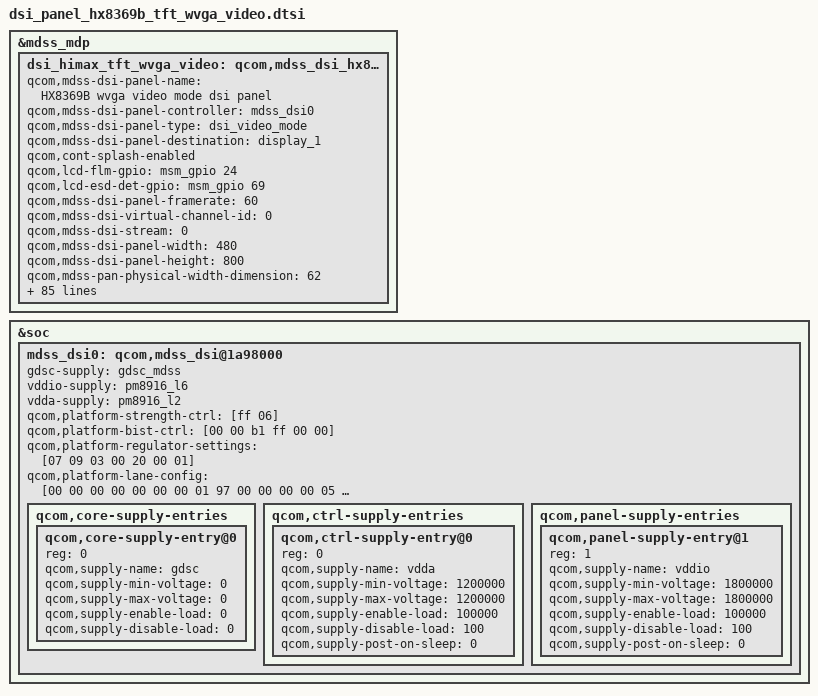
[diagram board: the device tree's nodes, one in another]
/* Copyright (c) 2013-14, Samsung Electronics Corporation. All rights reserved.
 *
 * This program is free software; you can redistribute it and/or modify
 * it under the terms of the GNU General Public License version 2 and
 * only version 2 as published by the Free Software Foundation.
 *
 * This program is distributed in the hope that it will be useful,
 * but WITHOUT ANY WARRANTY; without even the implied warranty of
 * MERCHANTABILITY or FITNESS FOR A PARTICULAR PURPOSE.  See the
 * GNU General Public License for more details.
 */

/*---------------------------------------------------------------------------
 * This file is autogenerated file using gcdb parser. Please do not edit it.
 * Update input XML file to add a new entry or update variable in this file
 * VERSION = "1.0"
 *---------------------------------------------------------------------------

 */
&mdss_mdp {
	dsi_himax_tft_wvga_video: qcom,mdss_dsi_hx8369b_wvga_video {
		qcom,mdss-dsi-panel-name = "HX8369B wvga video mode dsi panel";
		qcom,mdss-dsi-panel-controller = <&mdss_dsi0>;
		qcom,mdss-dsi-panel-type = "dsi_video_mode";
		qcom,mdss-dsi-panel-destination = "display_1";
		qcom,cont-splash-enabled;
		qcom,lcd-flm-gpio = <&msm_gpio 24 0>;
		qcom,lcd-esd-det-gpio = <&msm_gpio 69 0>;
		qcom,mdss-dsi-panel-framerate = <60>;
		qcom,mdss-dsi-virtual-channel-id = <0>;
		qcom,mdss-dsi-stream = <0>;
		qcom,mdss-dsi-panel-width = <480>;
		qcom,mdss-dsi-panel-height = <800>;
		qcom,mdss-pan-physical-width-dimension = <62>; /* <Width> real size of panel in mm */
		qcom,mdss-pan-physical-height-dimension = <106>; /*<Height> real size of panel in mm */
		qcom,mdss-dsi-lp11-init;
		qcom,mdss-dsi-init-delay-us = <100>;
		qcom,mdss-dsi-h-front-porch = <110>;
		qcom,mdss-dsi-h-back-porch = <246>;
		qcom,mdss-dsi-h-pulse-width = <4>;
		qcom,mdss-dsi-h-sync-skew = <0>;
		qcom,mdss-dsi-v-back-porch = <12>;
		qcom,mdss-dsi-v-front-porch = <10>;
		qcom,mdss-dsi-v-pulse-width = <4>;
		qcom,mdss-dsi-h-front-porch-dtc = <110>;
		qcom,mdss-dsi-h-back-porch-dtc = <110>;
		qcom,mdss-dsi-h-pulse-width-dtc = <4>;
		qcom,mdss-dsi-v-back-porch-dtc = <12>;
		qcom,mdss-dsi-v-front-porch-dtc= <10>;
		qcom,mdss-dsi-v-pulse-width-dtc = <4>;
		qcom,mdss-dsi-h-front-porch-sc7798a-boe = <140>;/*<SC7798A porch&timing>*/
		qcom,mdss-dsi-h-back-porch-sc7798a-boe = <132>;
		qcom,mdss-dsi-h-pulse-width-sc7798a-boe = <4>;
		qcom,mdss-dsi-v-front-porch-sc7798a-boe= <10>;
		qcom,mdss-dsi-v-back-porch-sc7798a-boe = <12>;
		qcom,mdss-dsi-v-pulse-width-sc7798a-boe = <4>;
		qcom,mdss-dsi-panel-timings-sc7798a-boe = [33 1A 10 00 3E 40 16 1E 15 03 04 00];
		qcom,mdss-dsi-t-clk-pre-sc7798a-boe = <0x18>;
		qcom,mdss-dsi-t-clk-post-sc7798a-boe = <0x04>;/*<END SC7798A porch&timing>*/
		qcom,mdss-dsi-h-front-porch-boe = <110>;
		qcom,mdss-dsi-h-back-porch-boe = <110>;
		qcom,mdss-dsi-h-back-porch-boe-ctc = <110>;/*MIPI 408Mhz porch for Rossa CTC*/
		qcom,mdss-dsi-h-pulse-width-boe = <4>;
		qcom,mdss-dsi-v-back-porch-boe = <12>;
		qcom,mdss-dsi-v-front-porch-boe= <10>;
		qcom,mdss-dsi-v-pulse-width-boe = <4>;
		qcom,mdss-dsi-h-left-border = <0>;
		qcom,mdss-dsi-h-right-border = <0>;
		qcom,mdss-dsi-v-top-border = <0>;
		qcom,mdss-dsi-v-bottom-border = <0>;
		qcom,mdss-dsi-bpp = <24>;
		qcom,mdss-dsi-color-order = <0>;
		qcom,mdss-dsi-underflow-color = <0xff>;
		qcom,mdss-dsi-border-color = <0>;
		qcom,mdss-dsi-dma-trigger = "trigger_sw";
		qcom,mdss-dsi-mdp-trigger = "none";
		qcom,mdss-dsi-bl-min-level = <1>;
		qcom,mdss-dsi-bl-max-level = <255>;
		qcom,mdss-dsi-bl-pmic-control-type = "bl_ctrl_dcs";
		qcom,mdss-dsi-lane-0-state;
		qcom,mdss-dsi-lane-1-state;
		qcom,mdss-dsi-bllp-eof-power-mode;
		qcom,mdss-dsi-bllp-power-mode;
		qcom,mdss-dsi-traffic-mode = "burst_mode";
		qcom,mdss-force-clk-lane-hs = <0>;
		qcom,mdss-dsi-reset-sequence = <1 20>, <0 1>, <1 20>;
		qcom,mdss-dsi-h-sync-pulse = <0>;
		qcom,mdss-dsi-panel-timings = [88 33 14 00 45 4A 19 37 23 03 04 00];
		qcom,mdss-dsi-t-clk-pre = <0x1D>;
		qcom,mdss-dsi-t-clk-post = <0x04>;
		qcom,mdss-dsi-panel-timings-dtc = [51 14 0C 00 36 38 12 18 1B 03 04 00];
		qcom,mdss-dsi-t-clk-pre-dtc = <0x15>;
		qcom,mdss-dsi-t-clk-post-dtc = <0x04>;
		qcom,mdss-dsi-panel-timings-boe = [E3 1A 10 00 3E 40 16 1E 15 03 04 00];
		qcom,mdss-dsi-panel-timings-boe-ctc = [88 33 14 00 45 4A 19 37 23 03 04 00];/*MIPI 408Mhz timing for Rossa CTC*/
		qcom,mdss-dsi-t-clk-pre-boe = <0x25>;
		qcom,mdss-dsi-t-clk-post-boe = <0x04>;
		qcom,mdss-dsi-on-command = [
					/* < Power Setting Sequence(1) > */
					39 01 00 00 00 00 06 F0 55 AA 52 08 01
					39 01 00 00 00 00 02 B0 08
					39 01 00 00 00 00 02 B2 40
					39 01 00 00 00 00 02 B3 28
					39 01 00 00 00 00 02 B4 19
					39 01 00 00 00 00 02 B5 54
					39 01 00 00 00 00 02 B9 36
					39 01 00 00 00 00 02 BA 26
					39 01 00 00 00 00 03 BC A0 00
					39 01 00 00 00 00 03 BD A0 00
					/* < Gamma Setting Sequence(3) > */
					39 01 00 00 00 00 11 D1 65 00 00 88 00 C9 00 D7 00 EB 01 12 01 33 01 65
					39 01 00 00 00 00 11 D2 01 8B 01 C2 01 EA 02 21 02 4C 02 4D 02 72 02 96
					39 01 00 00 00 00 11 D3 02 AA 02 C1 02 CF 02 E3 02 EF 02 FF 03 0B 03 1B
					39 01 00 00 00 00 05 D4 03 3A 03 9A
					39 01 00 00 00 00 11 D5 65 00 00 88 00 C9 00 D7 00 EB 01 12 01 33 01 65
					39 01 00 00 00 00 11 D6 01 8B 01 C2 01 EA 02 21 02 4C 02 4D 02 72 02 96
					39 01 00 00 00 00 11 D7 02 AA 02 C1 02 CF 02 E3 02 EF 02 FF 03 0B 03 1B
					39 01 00 00 00 00 05 D8 03 3A 03 9A
					39 01 00 00 00 00 11 D9 65 00 00 88 00 C9 00 D7 00 EB 01 12 01 33 01 65
					39 01 00 00 00 00 11 DD 01 8B 01 C2 01 EA 02 21 02 4C 02 4D 02 72 02 96
					39 01 00 00 00 00 11 DE 02 AA 02 C1 02 CF 02 E3 02 EF 02 FF 03 0B 03 1B
					39 01 00 00 00 00 05 DF 03 3A 03 9A
					39 01 00 00 00 00 11 E0 00 3B 00 5E 00 C9 00 D7 00 EB 01 12 01 33 01 65
					39 01 00 00 00 00 11 E1 01 8B 01 C2 01 EA 02 21 02 4C 02 4D 02 72 02 96
					39 01 00 00 00 00 11 E2 02 AA 02 C1 02 CF 02 E3 02 EF 02 FF 03 0B 03 1B
					39 01 00 00 00 00 05 E3 03 3A 03 9A
					39 01 00 00 00 00 11 E4 00 3B 00 5E 00 C9 00 D7 00 EB 01 12 01 33 01 65
					39 01 00 00 00 00 11 E5 01 8B 01 C2 01 EA 02 21 02 4C 02 4D 02 72 02 96
					39 01 00 00 00 00 11 E6 02 AA 02 C1 02 CF 02 E3 02 EF 02 FF 03 0B 03 1B
					39 01 00 00 00 00 05 E7 03 3A 03 9A
					39 01 00 00 00 00 11 E8 00 3B 00 5E 00 C9 00 D7 00 EB 01 12 01 33 01 65
					39 01 00 00 00 00 11 E9 01 8B 01 C2 01 EA 02 21 02 4C 02 4D 02 72 02 96
					39 01 00 00 00 00 11 EA 02 AA 02 C1 02 CF 02 E3 02 EF 02 FF 03 0B 03 1B
					39 01 00 00 00 00 05 EB 03 3A 03 9A
					/* < Initializing Sequence(2) > */
					39 01 00 00 00 00 06 F0 55 AA 52 08 00
					39 01 00 00 00 00 03 B1 16 00
					39 01 00 00 00 00 03 B3 61 02
					39 01 00 00 00 00 03 B4 08 50
					39 01 00 00 00 00 02 B6 03
					39 01 00 00 00 00 03 B7 F0 F0
					39 01 00 00 00 00 03 B8 01 07
					39 01 00 00 00 00 02 BC 02
					39 01 00 00 00 00 04 BB FF F5 00
					39 01 00 00 00 00 13 C8 80 00 46 64 46 64 46 64 46 64 64 FF FF 64 64 64 64 64
					39 01 00 00 00 00 02 B3 20
					39 01 00 00 00 00 06 F0 55 AA 52 00 00
					39 01 00 00 00 00 05 FF AA 55 25 01
					39 01 00 00 00 00 02 6F 02
					39 01 00 00 00 00 02 F4 57
					39 01 00 00 00 00 02 6F 13
					39 01 00 00 00 00 02 F2 16
					39 01 00 00 00 00 05 FF AA 55 25 00
					39 01 00 00 00 00 02 B3 20
					39 01 00 00 00 00 02 36 00
					39 01 00 00 00 00 02 35 00
					/* < Display on Sequence> */
					05 01 00 00 78 00 02 11 00
					05 01 00 00 0A 00 02 29 00
					/* Test Screen Mode */
					/*
					39 01 00 00 00 00 06 F0 55 AA 52 08 00
					39 01 00 00 00 00 05 EE 87 78 02 40
					*/
					39 01 00 00 00 00 02 55 00
					39 01 00 00 00 00 02 53 2C
					];
		qcom,mdss-dsi-on-command-dtc = [
					/* < Power Setting Sequence(1) > */
					39 01 00 00 00 00 06 F0 55 AA 52 08 01
					39 01 00 00 00 00 02 B0 0C
					39 01 00 00 00 00 02 B2 41
					39 01 00 00 00 00 02 B3 1E
					39 01 00 00 00 00 02 B4 19
					39 01 00 00 00 00 02 B5 64
					39 01 00 00 00 00 02 B9 36
					39 01 00 00 00 00 02 BA 26
					39 01 00 00 00 00 03 BC 66 00
					39 01 00 00 00 00 03 BD 66 00
					39 01 00 00 00 00 02 6F 02
					39 01 00 00 0A 00 02 C8 C0
					/* < Gamma Setting Sequence(3) > */
					39 01 00 00 00 00 11 D1 00 00 00 01 00 07 00 1D 00 3A 00 7A 00 AE 00 FC
					39 01 00 00 00 00 11 D2 01 33 01 7A 01 AB 01 EC 02 1D 02 1E 02 48 02 6F
					39 01 00 00 00 00 11 D3 02 82 02 99 02 A5 02 B4 02 BB 02 C4 02 C9 02 CF
					39 01 00 00 00 00 05 D4 02 D5 02 F0
					39 01 00 00 00 00 11 E0 00 00 00 01 00 07 00 1D 00 3A 00 7A 00 AE 00 FC
					39 01 00 00 00 00 11 E1 01 33 01 7A 01 AB 01 EC 02 1D 02 1E 02 48 02 6F
					39 01 00 00 00 00 11 E2 02 82 02 99 02 A5 02 B4 02 BB 02 C4 02 C9 02 CF
					39 01 00 00 00 00 05 E3 02 D5 02 F0
					39 01 00 00 00 00 11 D5 00 00 00 01 00 07 00 1D 00 3A 00 7A 00 AE 00 FC
					39 01 00 00 00 00 11 D6 01 33 01 7A 01 AB 01 EC 02 1D 02 1E 02 48 02 6F
					39 01 00 00 00 00 11 D7 02 82 02 99 02 A5 02 B4 02 BB 02 C4 02 C9 02 CF
					39 01 00 00 00 00 05 D8 02 D5 02 F0
					39 01 00 00 00 00 11 E4 00 00 00 01 00 07 00 1D 00 3A 00 7A 00 AE 00 FC
					39 01 00 00 00 00 11 E5 01 33 01 7A 01 AB 01 EC 02 1D 02 1E 02 48 02 6F
					39 01 00 00 00 00 11 E6 02 82 02 99 02 A5 02 B4 02 BB 02 C4 02 C9 02 CF
					39 01 00 00 00 00 05 E7 02 D5 02 F0
					39 01 00 00 00 00 11 D9 00 00 00 01 00 07 00 1D 00 3A 00 7A 00 AE 00 FC
					39 01 00 00 00 00 11 DD 01 33 01 7A 01 AB 01 EC 02 1D 02 1E 02 48 02 6F
					39 01 00 00 00 00 11 DE 02 82 02 99 02 A5 02 B4 02 BB 02 C4 02 C9 02 CF
					39 01 00 00 00 00 05 DF 02 D5 02 F0
					39 01 00 00 00 00 11 E8 00 00 00 01 00 07 00 1D 00 3A 00 7A 00 AE 00 FC
					39 01 00 00 00 00 11 E9 01 33 01 7A 01 AB 01 EC 02 1D 02 1E 02 48 02 6F
					39 01 00 00 00 00 11 EA 02 82 02 99 02 A5 02 B4 02 BB 02 C4 02 C9 02 CF
					39 01 00 00 00 00 05 EB 02 D5 02 F0
					/* < Initializing Sequence(2) > */
					39 01 00 00 00 00 06 F0 55 AA 52 08 00
					39 01 00 00 00 00 03 B1 16 00
					39 01 00 00 00 00 03 B3 61 02
					39 01 00 00 00 00 03 B4 09 50
					39 01 00 00 00 00 02 B6 03
					39 01 00 00 00 00 03 B7 00 00
					39 01 00 00 00 00 03 B8 11 11
					39 01 00 00 00 00 04 BB FF F5 00
					39 01 00 00 00 00 02 BC 00
					39 01 00 00 00 00 0B C9 D2 00 00 9A 00 80 C7 4A 41 04
					39 01 00 00 00 00 25 EC 10 10 10 10 04 0F 13 12 09 0A 0B 0C 05 06 07 08 0D 0E 03 04 09 0A 0B 0C 05 06 07 08 12 13 02 0D 10 10 10 10
					39 01 00 00 00 00 25 ED10 10 10 10 04 0F 13 12 09 0A 0B 0C 05 06 07 08 0D 0E 03 04 09 0A 0B 0C 05 06 07 08 12 13 02 0D 10 10 10 10
					39 01 00 00 00 00 06 F0 55 AA 52 00 00
					39 01 00 00 00 00 05 FF AA 55 25 01
					39 01 00 00 00 00 02 6F 13
					39 01 00 00 00 00 02 F2 16
					39 01 00 00 00 00 05 FF AA 55 25 00
					39 01 00 00 00 00 02 36 10
					/* < Display on Sequence> */
					05 01 00 00 78 00 02 11 00
					05 01 00 00 14 00 02 29 00
					/* Test Screen Mode */
					/*
					39 01 00 00 00 00 06 F0 55 AA 52 08 00
					39 01 00 00 00 00 05 EE 87 78 02 40
					*/
					39 01 00 00 00 00 02 55 00
					39 01 00 00 00 00 02 53 2C
					];
		qcom,mdss-dsi-on-command-hx8369b-dtc = [
					39 01 00 00 0A 00 04 B9 FF 83 69
					39 01 00 00 00 00 10 BA 31 00 16 CA B1 0A 00 10 28 02 21 21 9A 1A 8F
					39 01 00 00 00 00 5D D5 00 00 07 00 09 00 00 10 01 00 00 00 01 42 37
						00 00 08 2A 08 47 00 00 03 00 00 00 00 00 00 00 00 00 00 00 15
						00 00 98 98 44 66 00 22 51 00 00 89 98 33 11 77 55 00 00 00 98
						98 55 77 11 33 40 00 00 89 98 22 00 66 44 15 00 00 00 01 00 00
						00 03 00 0F FF FF 03 00 0F FF FF 00 8C 5A
					39 01 00 00 00 00 02 3A 70
					39 01 00 00 00 00 02 36 00
					39 01 00 00 00 00 0B B1 0B 83 77 00 0F 0F 17 17 0C 1A
					39 01 00 00 00 00 02 B2 03
					39 01 00 00 00 00 05 B3 83 00 31 03
					39 01 00 00 00 00 02 B4 00
					39 01 00 00 00 00 03 B6 A3 A3
					39 01 00 00 00 00 02 CC 0C
					39 01 00 00 00 00 07 C0 73 50 00 34 C4 00
					39 01 00 00 00 00 05 E3 00 00 00 00
					39 01 00 00 00 00 02 EA 72
					39 01 00 00 00 00 02 C6 41
					39 01 00 00 00 00 24 E0 01 0D 18 17 12 2F 31 3C 09 10 11 16 17 16 16 12 15 01 0D 18 17 12 2F 31 3C 09 10 11 16 17 16 16 12 15 01
					39 01 00 00 00 00 03 C9 0F 00
					39 01 00 00 00 00 02 55 00
					39 01 00 00 00 00 02 53 24
					05 01 00 00 B4 00 02 11 00
					05 01 00 00 0A 00 02 29 00
					];
		qcom,mdss-dsi-on-command-boe = [
					/* < Power Setting Sequence(1) > */
					39 01 00 00 00 00 04 B9 FF 83 69
					39 01 00 00 00 00 0B B1 0B 83 77 00 0F 0F 0B 0B 0C 0A
					39 01 00 00 00 00 04 C6 41 FF 7D	
					39 01 00 00 00 00 05 E3 00 00 00 00 
					39 01 00 00 00 00 07 C0 73 50 00 34 C4 00
					/* < Power Setting Sequence(2) > */
					39 01 00 00 00 00 10 BA 31 00 16 CA B1 0A 00 10 28 02 21 21 9A 1A 8F 
					39 01 00 00 00 00 02 3A 70
					39 01 00 00 00 00 05 B3 83 00 31 03	
					39 01 00 00 00 00 02 B4 00
					39 01 00 00 00 00 02 CC 0E
					39 01 00 00 00 00 02 EA 72
					39 01 00 00 00 00 02 B2 03
					39 01 00 00 00 00 5D D5 00 00 07 00 09 00 00 10 01 00 00 00 01 42 37
										 00 00 08 2A 08 47 00 00 03 00 00 00 00 00 00 00 		
										 00 00 00 00 15 00 00 98 98 44 66 00 22 51 00 00
										 89 98 33 11 77 55 04 00 00 98 98 55 77 11 33 40
										 00 00 89 98 22 00 66 44 15 00 00 00 01 00 00 00 
										 03 00 0F FF FF 03 00 0F FF FF 00 8C 5A 
					/* < Gamma Setting Sequence(3) > */
					39 01 00 00 00 00 24 E0 01 02 05 2C 33 3F 10 33 06 0D 0E 10 16 10 14
										 13 19 01 02 05 2C 32 3F 0E 30 08 0E 0F 12 11 14 
										 12 13 19 01
					/* < Display on Sequence> */
					39 01 00 00 00 00 03 C9 0F 01
					39 01 00 00 00 00 02 55 00
					39 01 00 00 00 00 02 53 24
					05 01 00 00 78 00 02 11 00
					05 01 00 00 0A 00 02 29 00
					];
		qcom,mdss-dsi-on-command-sc7798a-boe = [
					/* < Power Setting Sequence(1) > */
					39 01 00 00 00 00 04 B9 F1 08 00 //EXTC
					39 01 00 00 00 00 08 B1 31 0C 0C A7 33 01 B7 //POWER
					39 01 00 00 00 00 04 C6 00 00 FD //SOURCE EQ
					39 01 00 00 00 00 05 E3 03 03 03 03 //SOURCE EQ
					39 01 00 00 00 00 03 B8 06 22 //EXT POWER
					/* < Initializing Sequence(2) > */
					39 01 00 00 00 00 13 BA 31 00 44 25 91 0A 00 00 C2 34 00 00 04 02 1D B9 EE 40 //MIPI CHARACTERISTIC
					39 01 00 00 00 00 09 B3 00 00 00 00 0C 0A 25 20 //RGB INTERFACE
					39 01 00 00 00 00 02 B4 00 //COLVMN INVERTION
					39 01 00 00 00 00 02 CC 0E //DGC
					39 01 00 00 00 00 02 BC 67 //VDC
					39 01 00 00 00 00 02 B2 03 //PANEL RSO
					39 01 00 00 00 00 06 C0 73 50 00 08 70 //SCR
					39 01 00 00 00 00 34 E9 00 00 06 00 00 6E 29 12 30 00 48 08 6E 29 47 03 //GIP1 TIMMING
						00 00 00 00 00 18 00 00 89 98 33 11 77 55 13 00 00 89 98 22 00 66 44 02
						00 00 00 00 00 00 00 00 00 00 00
					39 01 00 00 00 00 25 EA 00 00 98 98 44 66 00 22 20 00 00 98 98 55 77 11 //GIP2 TIMMING
						33 31 30 00 00 FF 01 00 00 00 00 00 00 00 00 00 00 00 00 00
					/* < Gamma Setting Sequence(3) > */
					39 01 00 00 00 00 23 E0 01 09 0D 2E 36 3F 10 31 07 0D 11 15 13 16 15 32 //GAMMA
						38 01 05 05 30 35 3F 0E 30 04 09 0A 0D 12 0D 0F 2C 35
					/* < Display on Sequence> */
					39 01 00 00 00 00 02 C7 C0
					39 01 00 00 00 00 03 C8 11 01
					39 01 00 00 00 00 02 53 24
					05 01 00 00 78 00 02 11 00
					05 01 00 00 0A 00 02 29 00
					];
		samsung,panel-manufacture-id-read-cmds = [06 01 00 00 00 00 01 da 01
							06 01 00 00 00 00 01 db 01
							06 01 00 00 00 00 01 dc 01];

		qcom,mdss-dsi-on-command-state = "dsi_lp_mode";
		qcom,mdss-dsi-off-command-state = "dsi_hs_mode";
		qcom,mdss-dsi-off-command = [39 01 00 10  00 02 28 00
					39 01 00 00 46 00 02 10 00];
	};
};
&soc {
	mdss_dsi0: qcom,mdss_dsi@1a98000 {
		gdsc-supply = <&gdsc_mdss>;
		vddio-supply = <&pm8916_l6>;
		vdda-supply = <&pm8916_l2>;
		qcom,platform-strength-ctrl = [ff 06];
		qcom,platform-bist-ctrl = [00 00 b1 ff 00 00];
		qcom,platform-regulator-settings = [07 09 03 00 20 00 01];
		qcom,platform-lane-config = [00 00 00 00 00 00 00 01 97
			00 00 00 00 05 00 00 01 97
			00 00 00 00 0a 00 00 01 97
			00 00 00 00 0f 00 00 01 97
			00 c0 00 00 00 00 00 01 bb];
		qcom,core-supply-entries {
			#address-cells = <1>;
			#size-cells = <0>;

			qcom,core-supply-entry@0 {
				reg = <0>;
				qcom,supply-name = "gdsc";
				qcom,supply-min-voltage = <0>;
				qcom,supply-max-voltage = <0>;
				qcom,supply-enable-load = <0>;
				qcom,supply-disable-load = <0>;
			};
		};
		qcom,ctrl-supply-entries {
			#address-cells = <1>;
			#size-cells = <0>;

			qcom,ctrl-supply-entry@0 {
				reg = <0>;
				qcom,supply-name = "vdda";
				qcom,supply-min-voltage = <1200000>;
				qcom,supply-max-voltage = <1200000>;
				qcom,supply-enable-load = <100000>;
				qcom,supply-disable-load = <100>;
				qcom,supply-post-on-sleep = <0>;
			};
		};
		qcom,panel-supply-entries {
			#address-cells = <1>;
			#size-cells = <0>;

			qcom,panel-supply-entry@1 {
				reg = <1>;
				qcom,supply-name = "vddio";
				qcom,supply-min-voltage = <1800000>;
				qcom,supply-max-voltage = <1800000>;
				qcom,supply-enable-load = <100000>;
				qcom,supply-disable-load = <100>;
				qcom,supply-post-on-sleep = <0>;
			};
		};
	};
};

